# PIC32MZ2048EFM064 device description
Architecture: MIPS; Family: PIC32MZEF; Series: PIC32MZ
Registers are 32-bit, read-write, no defined reset value unless marked. A register's access mark holds for its fields unless they carry their own. Offsets are from the block's base; [hi:lo] are bit positions.

## RCON
Instances: RCON 0x1f801200 in periph_pb1_std
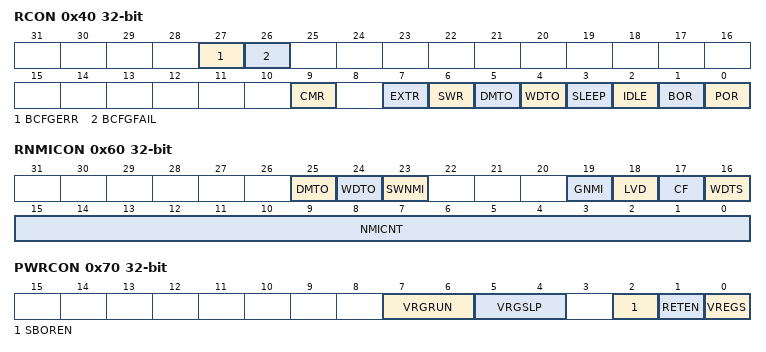
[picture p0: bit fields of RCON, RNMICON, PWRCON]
0x40 RCON — Reset Control Register
  [27] BCFGERR — Primary Configuration Registers Error Flag bit
    1=An error occurred during a read of the primary configuration registers; 0=No error occurred during a read of the primary configuration registers
  [26] BCFGFAIL — Primary/Secondary Configuration Registers Error Flag bit
    1=An error occurred during a read of the primary and alternate configuration registers; 0=No error occurred during a read of the primary and alternate configuration registers
  [9] CMR — Configuration Mismatch Reset Flag bit
    1=A Configuration Mismatch Reset has occurred; 0=A Configuration Mismatch Reset has not occurred
  [7] EXTR — External Reset (MCLR) Pin Flag bit
    1=Master Clear (pin) Reset has occurred; 0=Master Clear (pin) Reset has not occurred
  [6] SWR — Software Reset Flag bit
    1=Software Reset was executed; 0=Software Reset was not executed
  [5] DMTO — Deadman Timer Time-out Flag bit
    1=A DMT time-out has occurred; 0=A DMT time-out has not occurred
  [4] WDTO — Watchdog Timer Time-out Flag bit
    1=WDT Time-out has occurred; 0=WDT Time-out has not occurred
  [3] SLEEP — Wake From Sleep Flag bit
    1=Device was in Sleep mode; 0=Device was not in Sleep mode
  [2] IDLE — Wake From Idle Flag bit
    1=Device was in Idle mode; 0=Device was not in Idle mode
  [1] BOR — Brown-out Reset Flag bit
    1=Brown-out Reset has occurred; 0=Brown-out Reset has not occurred
  [0] POR — Power-on Reset Flag bit
    1=Power-on Reset has occurred; 0=Power-on Reset has not occurred
0x50 RSWRST wo — Software Reset Register
  [0] SWRST — Software Reset Trigger bit
    1=Enable software Reset event; 0=No effect
0x60 RNMICON — Non-maskable Interrupt (NMI) Control Register
  [25] DMTO — Deadman Timer Time-out Flag bit
    1=DMT time-out has occurred and caused a NMI; 0=DMT time-out has not occurred
  [24] WDTO — Watchdog Timer Time-Out Flag bit
    1=WDT time-out has occurred and caused a NMI; 0=WDT time-out has not occurred
  [23] SWNMI — Software NMI Trigger
    1=An NMI will be generated; 0=An NMI will not be generated
  [19] GNMI — General NMI bit
    1=A general NMI event has been detected or a user-initiated NMI event has occurred; 0=A general NMI event has not been detected
  [18] LVD
  [17] CF — Clock Fail Detect bit
    1=FSCM has detected clock failure and caused an NMI; 0=FSCM has not detected clock failure
  [16] WDTS — Watchdog Timer Time-out in Sleep Mode Flag bit
    1=WDT time-out has occurred during Sleep mode and caused a wake-up from sleep; 0=WDT time-out has not occurred during Sleep mode
  [15:0] NMICNT — NMI Reset Counter Value bits
    0xffff=65535 SYSCLK cycles before a device Reset occurs; 1=1 SYSCLK cycle before a device Reset occurs; 0=No delay between NMI assertion and device Reset event
0x70 PWRCON — Power Control Register
  [7:6] VRGRUN
  [5:4] VRGSLP
  [2] SBOREN
  [1] RETEN
  [0] VREGS — Voltage Regulator Stand-by Enable bit
    1=Voltage regulator will remain active during Sleep; 0=Voltage regulator will go to Stand-by mode during Sleep

## CRYPTO
Instances: CRYPTO 0x1f8e5000 in periph_indep
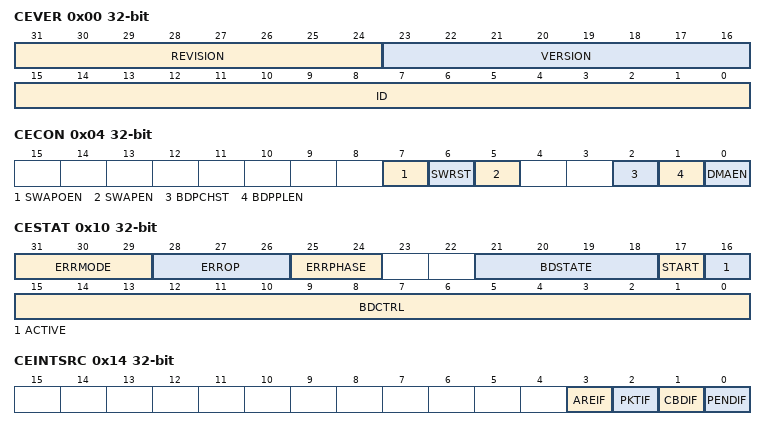
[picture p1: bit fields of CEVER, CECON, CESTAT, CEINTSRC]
0x00 CEVER ro — Crypto Engine Revision
  [31:24] REVISION, [23:16] VERSION, [15:0] ID
0x04 CECON — Crypto Engine Control Register
  [7] SWAPOEN — Swap Output Data Enable bit
    1=Output data is byte swapped when written by dedicated DMA; 0=Output data is not byte swapped when written by dedicated DMA
  [6] SWRST — Software Reset bit
    1=Initiate a software reset of the Crypto Engine; 0=Normal operation
  [5] SWAPEN — Input Data Swap Enable bit
    1=Input data is byte swapped when read by dedicated DMA; 0=Input data is not byte swapped when read by dedicated DMA
  [2] BDPCHST — Buffer Descriptor Processor Fetch Enable bit
    1=BDP descriptor fetch is enabled; 0=BDP descriptor fetch is disabled
  [1] BDPPLEN — Buffer Descriptor Processor Poll Enable bit
    1=Poll for descriptor until valid bit is set; 0=Do not poll
  [0] DMAEN — DMA Enable bit
    1=Crypto Engine DMA is enabled; 0=Crypto Engine DMA is disabled
0x08 CEBDADDR ro — Crypto Engine Buffer Descriptor Register
  [31:0] BDPADDR
0x0C CEBDPADDR ro — Crypto Engine Buffer Descriptor Processor Register
  [31:0] BASEADDR
0x10 CESTAT ro — Crypto Engine Status Register
  [31:29] ERRMODE — Internal Error Mode Status bits
    3=CEK operation; 2=KEK operation; 1=Preboot authentication; 0=Normal operation
  [28:26] ERROP — Internal Error Operation Status bits
    4=Authentication; 2=Decryption; 1=Encryption
  [25:24] ERRPHASE — Internal Error Phase of DMA Status bits
    3=Destination data; 2=Source data; 1=Security Association (SA) access; 0=Buffer Descriptor (BD) access
  [21:18] BDSTATE — Buffer Descriptor Processor State Status bits
    6=SA fetch; 5=Fetch BDP is disabled; 4=Descriptor is done; 3=Data phase; 2=BDP is loading; 1=Descriptor fetch request is pending; 0=BDP is idle
  [17] START — DMA Start Status bit
    1=DMA start has occurred; 0=DMA start has not occurred
  [16] ACTIVE — Buffer Descriptor Processor Status bit
    1=BDP is active; 0=BDP is idle
  [15:0] BDCTRL
0x14 CEINTSRC ro — Crypto Engine Interrupt Source Register
  [3] AREIF — Access Response Error Interrupt bit
    1=Error occurred trying to access memory outside the Crypto Engine; 0=No error has occurred
  [2] PKTIF — DMA Packet Completion Interrupt Status bit
    1=DMA packet was completed; 0=DMA packet was not completed
  [1] CBDIF — BD Transmit Status bit
    1=Last BD transmit was processed; 0=Last BD transmit has not been processed
  [0] PENDIF — Crypto Engine Interrupt Pending Status bit
    1=Crypto Engine interrupt is pending (this value is the result of an OR of all interrupts in the Crypto Engine); 0=Crypto Engine interrupt is not pending
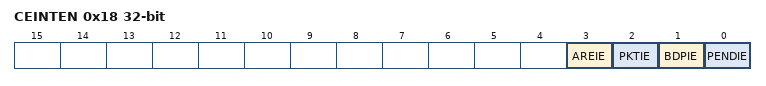
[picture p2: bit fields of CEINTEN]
0x18 CEINTEN — Crypto Engine Interrupt Enable Register
  [3] AREIE — Access Response Error Interrupt Enable bit
    1=Access response error interrupts are enabled; 0=Access response error interrupts are not enabled
  [2] PKTIE — DMA Packet Completion Interrupt Enable bit
    1=DMA packet completion interrupts are enabled; 0=DMA packet completion interrupts are not enabled
  [1] BDPIE — DMA Buffer Descriptor Processor Interrupt Enable bit
    1=BDP interrupts are enabled; 0=BDP interrupts are not enabled
  [0] PENDIE — Master Interrupt Enable bit
    1=Crypto Engine interrupts are enabled; 0=Crypto Engine interrupts are not enabled
0x1C CEPOLLCON — Crypto Engine Poll Control Register
  [15:0] BDPPLCON
0x20 CEHDLEN — Crypto Engine Header Length Register
  [7:0] HDRLEN
0x24 CETRLLEN — Crypto Engine Trailer Length Register
  [7:0] TRLRLEN

## Notices in the file
Copyright (c) 2017 Microchip Technology Inc.
SPDX-License-Identifier: Apache-2.0
Licensed under the Apache License, Version 2.0 (the "License");
you may not use this file except in compliance with the License.
You may obtain a copy of the License at
http://www.apache.org/licenses/LICENSE-2.0
Unless required by applicable law or agreed to in writing, software
distributed under the License is distributed on an "AS IS" BASIS,
WITHOUT WARRANTIES OR CONDITIONS OF ANY KIND, either express or implied.
See the License for the specific language governing permissions and
limitations under the License.
